# PIC32MX130F256B device description
Architecture: MIPS; Family: PIC32MX; Series: PIC32MX
Registers are 32-bit, read-write, no defined reset value unless marked. A register's access mark holds for its fields unless they carry their own. Offsets are from the block's base; [hi:lo] are bit positions; {n}, {i} and the like mark numbered series; 'fields as' and 'values as' point back to an identical list.

## CMP
Instances: CMP 0x1f80a000 in periph0
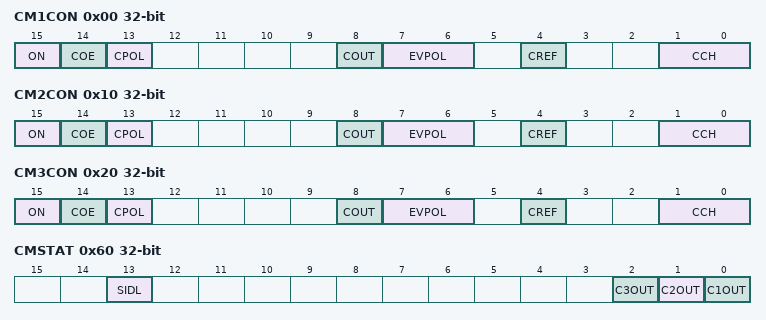
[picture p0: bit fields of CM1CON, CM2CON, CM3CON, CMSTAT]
0x00 CM1CON — Comparator Control Register
  [15] ON — Comparator ON bit
    1=Module is enabled. Setting this bit does not affect the other bits in this register; 0=Module is disabled and does not consume current. Clearing this bit does not affect the other bits in this register
  [14] COE — Comparator Output Enable bit
    1=Comparator output is driven on the output CxOUT pin; 0=Comparator output is not driven on the output CxOUT pin
  [13] CPOL — Comparator Output Inversion bit
    1=Output is inverted; 0=Output is not inverted
  [8] COUT — Comparator Output bit
    1=Output of the Comparator is a 1; 0=Output of the Comparator is a 0
  [7:6] EVPOL — Interrupt Event Polarity Select bits
    3=Comparator interrupt is generated on a low-to-high or high-to-low transition of the comparator output; 2=Comparator interrupt is generated on a high-to-low transition of the comparator output; 1=Comparator interrupt is generated on a low-to-high transition of the comparator output; 0=Comparator interrupt generation is disabled
  [4] CREF — Comparator Positive Input Configure bit
    1=Comparator non-inverting input is connected to the internal CVref; 0=Comparator non-inverting input is connected to the CxINA pin
  [1:0] CCH — Comparator Negative Input Select bits for Comparator
    3=Comparator inverting input is connected to the IVREF; 2=Comparator inverting input is connected to the CxIND pin; 1=Comparator inverting input is connected to the CxINC pin; 0=Comparator inverting input is connected to the CxINB pin
0x10 CM2CON — Comparator Control Register
  fields as CM1CON
0x20 CM3CON — Comparator Control Register
  fields as CM1CON
0x60 CMSTAT — Comparator Status Register
  [13] SIDL — Stop in Idle Control bit
    1=All Comparator modules are disabled when the device enters Idle mode; 0=All Comparator modules continue to operate when the device enters Idle mode
  [2] C3OUT — Comparator Output bit
    1=Output of Comparator 3 is a 1; 0=Output of Comparator 3 is a 0
  [1] C2OUT — Comparator Output bit
    1=Output of Comparator 2 is a 1; 0=Output of Comparator 2 is a 0
  [0] C1OUT — Comparator Output bit
    1=Output of Comparator 1 is a 1; 0=Output of Comparator 1 is a 0

## CORE
Instances: CORE 0x0
0x00 zero ro
0x04 at
0x08 v0
0x0C v1
{0x10+4i} a{i} (i=0..3)
{0x20+4i} t{i} (i=0..7)
{0x40+4i} s{i} (i=0..7)
0x60 t8
0x64 t9
0x68 k0
0x6C k1
0x70 gp
0x74 sp
0x78 fp
0x7C ra
0x80 HWREna
  [3:0] Mask
0x84 BadVAddr ro
0x88 Count
0x8C Compare
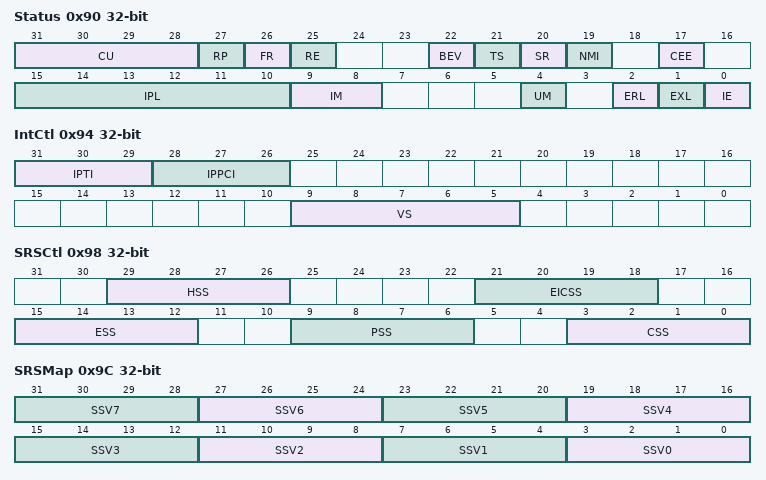
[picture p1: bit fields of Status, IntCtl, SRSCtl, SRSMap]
0x90 Status
  [31:28] CU, [27] RP, [26] FR, [25] RE, [22] BEV, [21] TS, [20] SR, [19] NMI, [17] CEE, [15:10] IPL, [9:8] IM, [4] UM, [2] ERL, [1] EXL, [0] IE
0x94 IntCtl
  [31:29] IPTI, [28:26] IPPCI, [9:5] VS
0x98 SRSCtl
  [29:26] HSS, [21:18] EICSS, [15:12] ESS, [9:6] PSS, [3:0] CSS
0x9C SRSMap
  [4n+3:4n] SSV{n} (n=0..7)
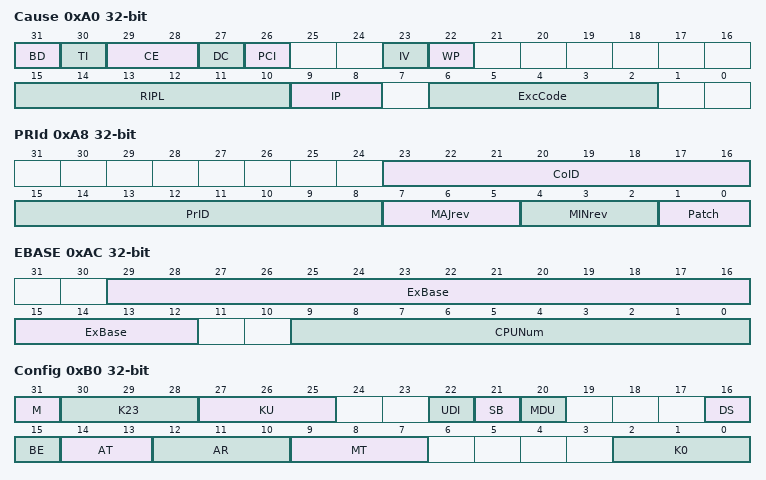
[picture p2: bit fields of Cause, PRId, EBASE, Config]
0xA0 Cause
  [31] BD, [30] TI, [29:28] CE, [27] DC, [26] PCI, [23] IV, [22] WP, [15:10] RIPL, [9:8] IP, [6:2] ExcCode
0xA4 EPC
0xA8 PRId ro
  [23:16] CoID, [15:8] PrID, [7:5] MAJrev, [4:2] MINrev, [1:0] Patch
0xAC EBASE
  [29:12] ExBase, [9:0] CPUNum
0xB0 Config
  [31] M, [30:28] K23, [27:25] KU, [22] UDI, [21] SB, [20] MDU, [16] DS, [15] BE, [14:13] AT, [12:10] AR, [9:7] MT, [2:0] K0
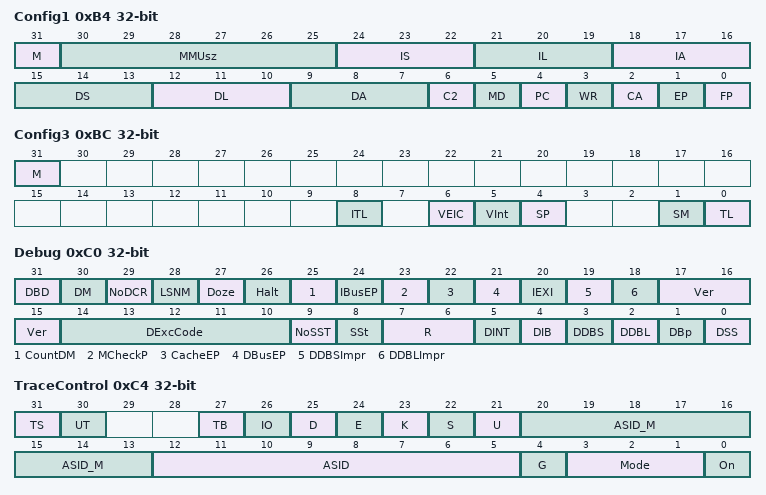
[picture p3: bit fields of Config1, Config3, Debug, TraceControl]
0xB4 Config1 ro
  [31] M, [30:25] MMUsz, [24:22] IS, [21:19] IL, [18:16] IA, [15:13] DS, [12:10] DL, [9:7] DA, [6] C2, [5] MD, [4] PC, [3] WR, [2] CA, [1] EP, [0] FP
0xB8 Config2 ro
  [31] M
0xBC Config3 ro
  [31] M, [8] ITL, [6] VEIC, [5] VInt, [4] SP, [1] SM, [0] TL
0xC0 Debug
  [31] DBD, [30] DM, [29] NoDCR, [28] LSNM, [27] Doze, [26] Halt, [25] CountDM, [24] IBusEP, [23] MCheckP, [22] CacheEP, [21] DBusEP, [20] IEXI, [19] DDBSImpr, [18] DDBLImpr, [17:15] Ver, [14:10] DExcCode, [9] NoSST, [8] SSt, [7:6] R, [5] DINT, [4] DIB, [3] DDBS, [2] DDBL, [1] DBp, [0] DSS
0xC4 TraceControl
  [31] TS, [30] UT, [27] TB, [26] IO, [25] D, [24] E, [23] K, [22] S, [21] U, [20:13] ASID_M, [12:5] ASID, [4] G, [3:1] Mode, [0] On
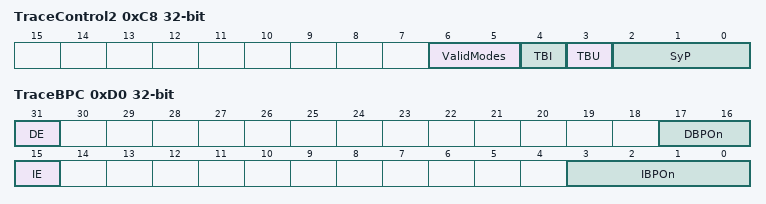
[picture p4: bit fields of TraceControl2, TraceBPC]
0xC8 TraceControl2 ro
  [6:5] ValidModes, [4] TBI, [3] TBU, [2:0] SyP
0xCC UserTraceData
  [31:0] Data
0xD0 TraceBPC
  [31] DE, [17:16] DBPOn, [15] IE, [3:0] IBPOn
0xD4 Debug2
0xD8 DEPC
0xDC ErrorEPC
0xE0 DESAVE
0xE4 lo
  [31:0] MDUlow
0xE8 hi
  [31:0] MDUhigh

## Notices in the file
Copyright (c) 2019 Microchip Technology Inc.
SPDX-License-Identifier: Apache-2.0
Licensed under the Apache License, Version 2.0 (the "License");
you may not use this file except in compliance with the License.
You may obtain a copy of the License at
http://www.apache.org/licenses/LICENSE-2.0
Unless required by applicable law or agreed to in writing, software
distributed under the License is distributed on an "AS IS" BASIS,
WITHOUT WARRANTIES OR CONDITIONS OF ANY KIND, either express or implied.
See the License for the specific language governing permissions and
limitations under the License.
